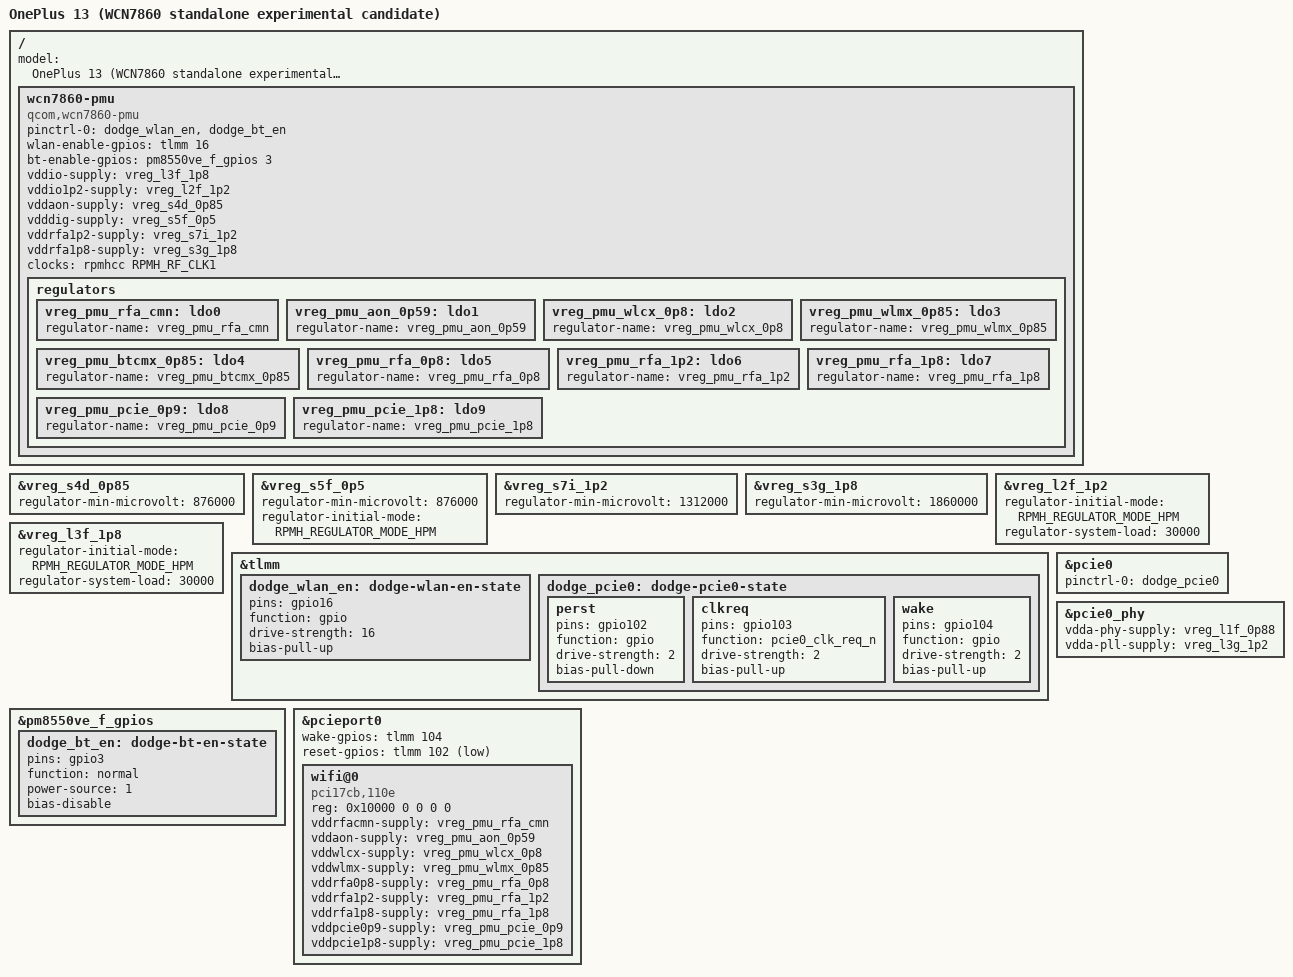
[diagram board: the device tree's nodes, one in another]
// SPDX-License-Identifier: BSD-3-Clause
/*
 * PMU output graph adapted from sm8750-erhai.dts, Copyright(c)2026 Erwin,
 * pinned7a81d184e309. Phone rails/pins from the owner's stock FDT and
 * OnePlusOSS d50b305f. Experimental WLAN-only candidate; no firmware/BDF.
 */
#include "sm8750-oneplus-dodge.dts"

/ {
	model = "OnePlus 13 (WCN7860 standalone experimental candidate)";
	wcn7860-pmu {
		compatible = "qcom,wcn7860-pmu";

		pinctrl-names = "default";
		pinctrl-0 = <&dodge_wlan_en>, <&dodge_bt_en>;

		wlan-enable-gpios = <&tlmm 16 GPIO_ACTIVE_HIGH>;
		bt-enable-gpios = <&pm8550ve_f_gpios 3 GPIO_ACTIVE_HIGH>;

		vddio-supply = <&vreg_l3f_1p8>;
		vddio1p2-supply = <&vreg_l2f_1p2>;
		vddaon-supply = <&vreg_s4d_0p85>;
		vdddig-supply = <&vreg_s5f_0p5>;
		vddrfa1p2-supply = <&vreg_s7i_1p2>;
		vddrfa1p8-supply = <&vreg_s3g_1p8>;

		clocks = <&rpmhcc RPMH_RF_CLK1>;

		regulators {
			vreg_pmu_rfa_cmn: ldo0 {
				regulator-name = "vreg_pmu_rfa_cmn";
			};

			vreg_pmu_aon_0p59: ldo1 {
				regulator-name = "vreg_pmu_aon_0p59";
			};

			vreg_pmu_wlcx_0p8: ldo2 {
				regulator-name = "vreg_pmu_wlcx_0p8";
			};

			vreg_pmu_wlmx_0p85: ldo3 {
				regulator-name = "vreg_pmu_wlmx_0p85";
			};

			vreg_pmu_btcmx_0p85: ldo4 {
				regulator-name = "vreg_pmu_btcmx_0p85";
			};

			vreg_pmu_rfa_0p8: ldo5 {
				regulator-name = "vreg_pmu_rfa_0p8";
			};

			vreg_pmu_rfa_1p2: ldo6 {
				regulator-name = "vreg_pmu_rfa_1p2";
			};

			vreg_pmu_rfa_1p8: ldo7 {
				regulator-name = "vreg_pmu_rfa_1p8";
			};

			vreg_pmu_pcie_0p9: ldo8 {
				regulator-name = "vreg_pmu_pcie_0p9";
			};

			vreg_pmu_pcie_1p8: ldo9 {
				regulator-name = "vreg_pmu_pcie_1p8";
			};
		};
	};

};

/* Stock consumer requests, not the broader unconstrained parent ranges. */
&vreg_s4d_0p85 { regulator-min-microvolt = <876000>; };
&vreg_s5f_0p5 {
	regulator-min-microvolt = <876000>;
	regulator-initial-mode = <RPMH_REGULATOR_MODE_HPM>;
};
&vreg_s7i_1p2 { regulator-min-microvolt = <1312000>; };
&vreg_s3g_1p8 { regulator-min-microvolt = <1860000>; };
&vreg_l2f_1p2 {
	regulator-initial-mode = <RPMH_REGULATOR_MODE_HPM>;
	regulator-system-load = <30000>;
};
&vreg_l3f_1p8 {
	regulator-initial-mode = <RPMH_REGULATOR_MODE_HPM>;
	regulator-system-load = <30000>;
};

&tlmm {
	dodge_wlan_en: dodge-wlan-en-state {
		pins = "gpio16";
		function = "gpio";
		drive-strength = <16>;
		bias-pull-up;
		/* The sequencer owns output level; no pinctrl output-high. */
	};
	dodge_pcie0: dodge-pcie0-state {
		perst { pins = "gpio102"; function = "gpio";
			drive-strength = <2>; bias-pull-down; };
		clkreq { pins = "gpio103"; function = "pcie0_clk_req_n";
			drive-strength = <2>; bias-pull-up; };
		wake { pins = "gpio104"; function = "gpio";
			drive-strength = <2>; bias-pull-up; };
	};
};

&pm8550ve_f_gpios {
	dodge_bt_en: dodge-bt-en-state {
		pins = "gpio3";
		function = "normal";
		power-source = <1>;
		bias-disable;
	};
};

&pcie0 { pinctrl-names = "default"; pinctrl-0 = <&dodge_pcie0>; status = "okay"; };
&pcie0_phy {
	/* Same-SoC reference candidates, not independently measured phone rails. */
	vdda-phy-supply = <&vreg_l1f_0p88>;
	vdda-pll-supply = <&vreg_l3g_1p2>;
	status = "okay";
};
&pcieport0 {
	wake-gpios = <&tlmm 104 GPIO_ACTIVE_HIGH>;
	reset-gpios = <&tlmm 102 GPIO_ACTIVE_LOW>;
	wifi@0 {
		compatible = "pci17cb,110e";
		reg = <0x10000 0 0 0 0>;
		vddrfacmn-supply = <&vreg_pmu_rfa_cmn>;
		vddaon-supply = <&vreg_pmu_aon_0p59>;
		vddwlcx-supply = <&vreg_pmu_wlcx_0p8>;
		vddwlmx-supply = <&vreg_pmu_wlmx_0p85>;
		vddrfa0p8-supply = <&vreg_pmu_rfa_0p8>;
		vddrfa1p2-supply = <&vreg_pmu_rfa_1p2>;
		vddrfa1p8-supply = <&vreg_pmu_rfa_1p8>;
		vddpcie0p9-supply = <&vreg_pmu_pcie_0p9>;
		vddpcie1p8-supply = <&vreg_pmu_pcie_1p8>;
	};
};
